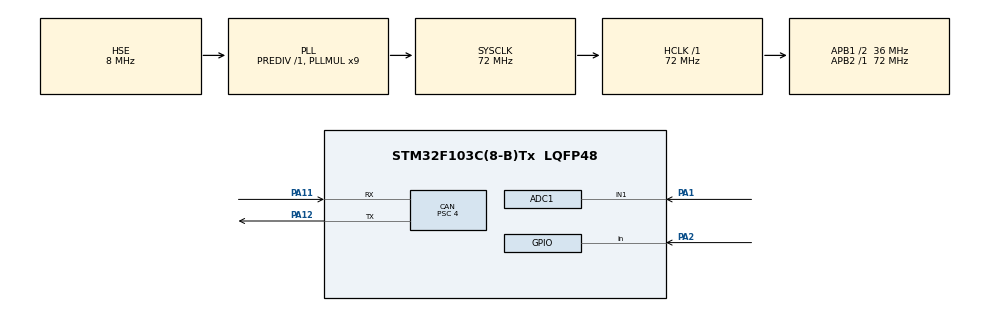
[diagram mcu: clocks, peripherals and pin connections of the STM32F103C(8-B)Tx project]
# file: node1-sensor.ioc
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ADC1.Channel-0\#ChannelRegularConversion=ADC_CHANNEL_1
ADC1.NbrOfConversionFlag=1
ADC1.Rank-0\#ChannelRegularConversion=1
ADC1.SamplingTime-0\#ChannelRegularConversion=ADC_SAMPLETIME_239CYCLES_5
ADC1.master=1
CAN.BS1=CAN_BS1_15TQ
CAN.BS2=CAN_BS2_2TQ
CAN.CalculateBaudRate=500000
CAN.CalculateTimeBit=2000
CAN.CalculateTimeQuantum=111.11111111111111
CAN.Prescaler=4
FREERTOS.INCLUDE_uxTaskGetStackHighWaterMark=1
FREERTOS.INCLUDE_vTaskDelayUntil=1
FREERTOS.Tasks01=defaultTask,0,128,StartDefaultTask,Default,NULL,Dynamic,NULL,NULL
FREERTOS.configCHECK_FOR_STACK_OVERFLOW=2
FREERTOS.configTOTAL_HEAP_SIZE=6144
FREERTOS.configUSE_NEWLIB_REENTRANT=1
Mcu.Family=STM32F1
Mcu.Name=STM32F103C(8-B)Tx
Mcu.Package=LQFP48
NVIC.PriorityGroup=NVIC_PRIORITYGROUP_4
NVIC.TIM4_IRQn=true\:15\:0\:false\:false\:true\:false\:false\:true\:true
NVIC.TimeBase=TIM4_IRQn
NVIC.TimeBaseIP=TIM4
NVIC.USB_LP_CAN1_RX0_IRQn=true\:5\:0\:false\:false\:true\:true\:true\:true\:true
PA1.Signal=ADCx_IN1
PA11.Mode=CAN_Activate
PA11.Signal=CAN_RX
PA12.Mode=CAN_Activate
PA12.Signal=CAN_TX
PA13.Mode=Serial_Wire
PA13.Signal=SYS_JTMS-SWDIO
PA14.Mode=Serial_Wire
PA14.Signal=SYS_JTCK-SWCLK
PA2.GPIO_PuPd=GPIO_PULLUP
PA2.Signal=GPIO_Input
PD0-OSC_IN.Mode=HSE-External-Oscillator
PD0-OSC_IN.Signal=RCC_OSC_IN
PD1-OSC_OUT.Mode=HSE-External-Oscillator
PD1-OSC_OUT.Signal=RCC_OSC_OUT
ProjectManager.HeapSize=0x200
ProjectManager.StackSize=0x400
ProjectManager.TargetToolchain=STM32CubeIDE
RCC.ADCPresc=RCC_ADCPCLK2_DIV6
RCC.AHBFreq_Value=72000000
RCC.APB1CLKDivider=RCC_HCLK_DIV2
RCC.APB1Freq_Value=36000000
RCC.APB1TimFreq_Value=72000000
RCC.APB2Freq_Value=72000000
RCC.APB2TimFreq_Value=72000000
RCC.HCLKFreq_Value=72000000
RCC.PLLMUL=RCC_PLL_MUL9
RCC.PLLSourceVirtual=RCC_PLLSOURCE_HSE
RCC.SYSCLKFreq_VALUE=72000000
RCC.SYSCLKSource=RCC_SYSCLKSOURCE_PLLCLK
RCC.USBFreq_Value=72000000
SH.ADCx_IN1.0=ADC1_IN1,IN1
TIM2.Prescaler=71
VP_FREERTOS_VS_CMSIS_V1.Mode=CMSIS_V1
VP_SYS_VS_tim4.Mode=TIM4
VP_TIM2_VS_ClockSourceINT.Mode=Internal
board=custom

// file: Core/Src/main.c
/* USER CODE BEGIN Header */
/**
  ******************************************************************************
  * @file           : main.c
  * @brief          : Main program body
  ******************************************************************************
  * @attention
  *
  * Copyright (c) 2026 STMicroelectronics.
  * All rights reserved.
  *
  * This software is licensed under terms that can be found in the LICENSE file
  * in the root directory of this software component.
  * If no LICENSE file comes with this software, it is provided AS-IS.
  *
  ******************************************************************************
  */
/* USER CODE END Header */
#include "main.h"
#include "cmsis_os.h"

/* USER CODE BEGIN Includes */
#include "app_ipc.h"
#include "bsp_board.h"
#include "task_can_tx.h"
#include "task_sensor.h"
/* USER CODE END Includes */

ADC_HandleTypeDef hadc1;

CAN_HandleTypeDef hcan;

TIM_HandleTypeDef htim2;

osThreadId defaultTaskHandle;

void SystemClock_Config(void);
static void MX_GPIO_Init(void);
static void MX_ADC1_Init(void);
static void MX_CAN_Init(void);
static void MX_TIM2_Init(void);
void StartDefaultTask(void const * argument);

int main(void)
{

  /* MCU Configuration--------------------------------------------------------*/

  /* Reset of all peripherals, Initializes the Flash interface and the Systick. */
  HAL_Init();

  /* Configure the system clock */
  SystemClock_Config();

  /* Initialize all configured peripherals */
  MX_GPIO_Init();
  MX_ADC1_Init();
  MX_CAN_Init();
  MX_TIM2_Init();
  /* USER CODE BEGIN 2 */
    bsp_board_init();
  /* USER CODE END 2 */

  /* USER CODE BEGIN RTOS_QUEUES */
    if (!app_ipc_init()) {
        Error_Handler();
    }
  /* USER CODE END RTOS_QUEUES */

  /* Create the thread(s) */
  /* definition and creation of defaultTask */
  osThreadDef(defaultTask, StartDefaultTask, osPriorityNormal, 0, 128);
  defaultTaskHandle = osThreadCreate(osThread(defaultTask), NULL);

  /* USER CODE BEGIN RTOS_THREADS */
    if (task_sensor_create() != pdPASS) {
        Error_Handler();
    }
    if (task_can_tx_create() != pdPASS) {
        Error_Handler();
    }
  /* USER CODE END RTOS_THREADS */

  /* Start scheduler */
  osKernelStart();

  /* We should never get here as control is now taken by the scheduler */

  /* Infinite loop */
    while (1) {

    }
}

void SystemClock_Config(void)
{
  RCC_OscInitTypeDef RCC_OscInitStruct = {0};
  RCC_ClkInitTypeDef RCC_ClkInitStruct = {0};
  RCC_PeriphCLKInitTypeDef PeriphClkInit = {0};

  /** Initializes the RCC Oscillators according to the specified parameters
  * in the RCC_OscInitTypeDef structure.
  */
  RCC_OscInitStruct.OscillatorType = RCC_OSCILLATORTYPE_HSE;
  RCC_OscInitStruct.HSEState = RCC_HSE_ON;
  RCC_OscInitStruct.HSEPredivValue = RCC_HSE_PREDIV_DIV1;
  RCC_OscInitStruct.HSIState = RCC_HSI_ON;
  RCC_OscInitStruct.PLL.PLLState = RCC_PLL_ON;
  RCC_OscInitStruct.PLL.PLLSource = RCC_PLLSOURCE_HSE;
  RCC_OscInitStruct.PLL.PLLMUL = RCC_PLL_MUL9;
  if (HAL_RCC_OscConfig(&RCC_OscInitStruct) != HAL_OK)
  {
    Error_Handler();
  }

  /** Initializes the CPU, AHB and APB buses clocks
  */
  RCC_ClkInitStruct.ClockType = RCC_CLOCKTYPE_HCLK|RCC_CLOCKTYPE_SYSCLK
                              |RCC_CLOCKTYPE_PCLK1|RCC_CLOCKTYPE_PCLK2;
  RCC_ClkInitStruct.SYSCLKSource = RCC_SYSCLKSOURCE_PLLCLK;
  RCC_ClkInitStruct.AHBCLKDivider = RCC_SYSCLK_DIV1;
  RCC_ClkInitStruct.APB1CLKDivider = RCC_HCLK_DIV2;
  RCC_ClkInitStruct.APB2CLKDivider = RCC_HCLK_DIV1;

  if (HAL_RCC_ClockConfig(&RCC_ClkInitStruct, FLASH_LATENCY_2) != HAL_OK)
  {
    Error_Handler();
  }
  PeriphClkInit.PeriphClockSelection = RCC_PERIPHCLK_ADC;
  PeriphClkInit.AdcClockSelection = RCC_ADCPCLK2_DIV6;
  if (HAL_RCCEx_PeriphCLKConfig(&PeriphClkInit) != HAL_OK)
  {
    Error_Handler();
  }
}

static void MX_ADC1_Init(void)
{

  ADC_ChannelConfTypeDef sConfig = {0};

  /** Common config
  */
  hadc1.Instance = ADC1;
  hadc1.Init.ScanConvMode = ADC_SCAN_DISABLE;
  hadc1.Init.ContinuousConvMode = DISABLE;
  hadc1.Init.DiscontinuousConvMode = DISABLE;
  hadc1.Init.ExternalTrigConv = ADC_SOFTWARE_START;
  hadc1.Init.DataAlign = ADC_DATAALIGN_RIGHT;
  hadc1.Init.NbrOfConversion = 1;
  if (HAL_ADC_Init(&hadc1) != HAL_OK)
  {
    Error_Handler();
  }

  /** Configure Regular Channel
  */
  sConfig.Channel = ADC_CHANNEL_1;
  sConfig.Rank = ADC_REGULAR_RANK_1;
  sConfig.SamplingTime = ADC_SAMPLETIME_239CYCLES_5;
  if (HAL_ADC_ConfigChannel(&hadc1, &sConfig) != HAL_OK)
  {
    Error_Handler();
  }

}

static void MX_CAN_Init(void)
{

  hcan.Instance = CAN1;
  hcan.Init.Prescaler = 4;
  hcan.Init.Mode = CAN_MODE_NORMAL;
  hcan.Init.SyncJumpWidth = CAN_SJW_1TQ;
  hcan.Init.TimeSeg1 = CAN_BS1_15TQ;
  hcan.Init.TimeSeg2 = CAN_BS2_2TQ;
  hcan.Init.TimeTriggeredMode = DISABLE;
  hcan.Init.AutoBusOff = DISABLE;
  hcan.Init.AutoWakeUp = DISABLE;
  hcan.Init.AutoRetransmission = DISABLE;
  hcan.Init.ReceiveFifoLocked = DISABLE;
  hcan.Init.TransmitFifoPriority = DISABLE;
  if (HAL_CAN_Init(&hcan) != HAL_OK)
  {
    Error_Handler();
  }

}

static void MX_TIM2_Init(void)
{

  TIM_ClockConfigTypeDef sClockSourceConfig = {0};
  TIM_MasterConfigTypeDef sMasterConfig = {0};

  htim2.Instance = TIM2;
  htim2.Init.Prescaler = 71;
  htim2.Init.CounterMode = TIM_COUNTERMODE_UP;
  htim2.Init.Period = 65535;
  htim2.Init.ClockDivision = TIM_CLOCKDIVISION_DIV1;
  htim2.Init.AutoReloadPreload = TIM_AUTORELOAD_PRELOAD_DISABLE;
  if (HAL_TIM_Base_Init(&htim2) != HAL_OK)
  {
    Error_Handler();
  }
  sClockSourceConfig.ClockSource = TIM_CLOCKSOURCE_INTERNAL;
  if (HAL_TIM_ConfigClockSource(&htim2, &sClockSourceConfig) != HAL_OK)
  {
    Error_Handler();
  }
  sMasterConfig.MasterOutputTrigger = TIM_TRGO_RESET;
  sMasterConfig.MasterSlaveMode = TIM_MASTERSLAVEMODE_DISABLE;
  if (HAL_TIMEx_MasterConfigSynchronization(&htim2, &sMasterConfig) != HAL_OK)
  {
    Error_Handler();
  }

}

static void MX_GPIO_Init(void)
{
  GPIO_InitTypeDef GPIO_InitStruct = {0};

  /* GPIO Ports Clock Enable */
  __HAL_RCC_GPIOD_CLK_ENABLE();
  __HAL_RCC_GPIOA_CLK_ENABLE();

  /*Configure GPIO pin : PA2 */
  GPIO_InitStruct.Pin = GPIO_PIN_2;
  GPIO_InitStruct.Mode = GPIO_MODE_INPUT;
  GPIO_InitStruct.Pull = GPIO_PULLUP;
  HAL_GPIO_Init(GPIOA, &GPIO_InitStruct);

}

void StartDefaultTask(void const * argument)
{
  /* USER CODE BEGIN 5 */
    (void)argument;
    vTaskDelete(NULL);
  /* USER CODE END 5 */
}

void HAL_TIM_PeriodElapsedCallback(TIM_HandleTypeDef *htim)
{
  if (htim->Instance == TIM4)
  {
    HAL_IncTick();
  }
}

void Error_Handler(void)
{
    __disable_irq();
    while (1) {
    }
}

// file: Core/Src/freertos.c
/* USER CODE BEGIN Header */
/**
  ******************************************************************************
  * File Name          : freertos.c
  * Description        : Code for freertos applications
  ******************************************************************************
  * @attention
  *
  * Copyright (c) 2026 STMicroelectronics.
  * All rights reserved.
  *
  * This software is licensed under terms that can be found in the LICENSE file
  * in the root directory of this software component.
  * If no LICENSE file comes with this software, it is provided AS-IS.
  *
  ******************************************************************************
  */
/* USER CODE END Header */

#include "FreeRTOS.h"
#include "task.h"
#include "main.h"

/* GetIdleTaskMemory prototype (linked to static allocation support) */
void vApplicationGetIdleTaskMemory( StaticTask_t **ppxIdleTaskTCBBuffer, StackType_t **ppxIdleTaskStackBuffer, uint32_t *pulIdleTaskStackSize );

/* Hook prototypes */
void vApplicationStackOverflowHook(xTaskHandle xTask, signed char *pcTaskName);

/* USER CODE BEGIN GET_IDLE_TASK_MEMORY */
static StaticTask_t xIdleTaskTCBBuffer;
static StackType_t xIdleStack[configMINIMAL_STACK_SIZE];

void vApplicationGetIdleTaskMemory(StaticTask_t **ppxIdleTaskTCBBuffer,
                                   StackType_t **ppxIdleTaskStackBuffer,
                                   uint32_t *pulIdleTaskStackSize) {
    *ppxIdleTaskTCBBuffer = &xIdleTaskTCBBuffer;
    *ppxIdleTaskStackBuffer = &xIdleStack[0];
    *pulIdleTaskStackSize = configMINIMAL_STACK_SIZE;
}
/* USER CODE END GET_IDLE_TASK_MEMORY */
